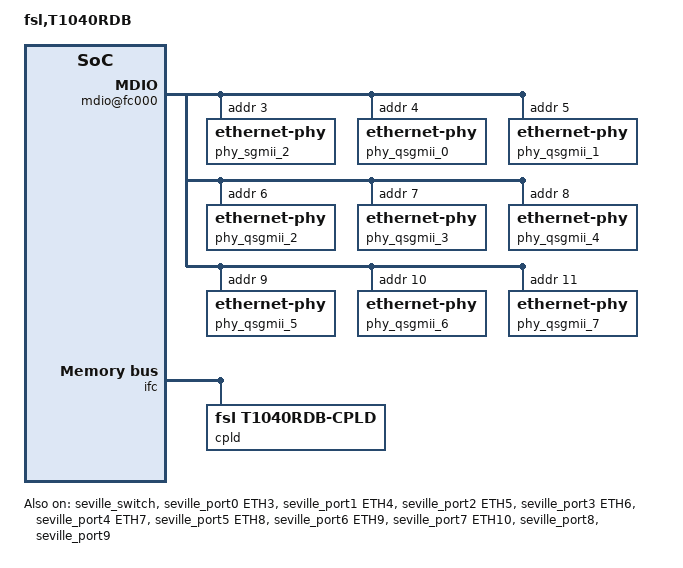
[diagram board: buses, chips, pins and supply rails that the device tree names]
/include/ "t104xsi-pre.dtsi"
/include/ "t104xrdb.dtsi"
/ {
	model = "fsl,T1040RDB";
	compatible = "fsl,T1040RDB";
	aliases {
		phy_sgmii_2 = &phy_sgmii_2;
	};
	soc@ffe000000 {
		fman@400000 {
			ethernet@e0000 {
				fixed-link = <0 1 1000 0 0>;
				phy-connection-type = "sgmii";
			};
			ethernet@e2000 {
				fixed-link = <1 1 1000 0 0>;
				phy-connection-type = "sgmii";
			};
			ethernet@e4000 {
				phy-handle = <&phy_sgmii_2>;
				phy-connection-type = "sgmii";
			};
			mdio@fc000 {
				phy_sgmii_2: ethernet-phy@3 {
					reg = <0x03>;
				};
				phy_qsgmii_0: ethernet-phy@4 {
					reg = <0x4>;
				};
				phy_qsgmii_1: ethernet-phy@5 {
					reg = <0x5>;
				};
				phy_qsgmii_2: ethernet-phy@6 {
					reg = <0x6>;
				};
				phy_qsgmii_3: ethernet-phy@7 {
					reg = <0x7>;
				};
				phy_qsgmii_4: ethernet-phy@8 {
					reg = <0x8>;
				};
				phy_qsgmii_5: ethernet-phy@9 {
					reg = <0x9>;
				};
				phy_qsgmii_6: ethernet-phy@a {
					reg = <0xa>;
				};
				phy_qsgmii_7: ethernet-phy@b {
					reg = <0xb>;
				};
			};
		};
	};
	ifc: localbus@ffe124000 {
		cpld@3,0 {
			compatible = "fsl,t1040rdb-cpld";
		};
	};
};
#include "t1040si-post.dtsi"
&seville_switch {
	status = "okay";
};
&seville_port0 {
	managed = "in-band-status";
	phy-handle = <&phy_qsgmii_0>;
	phy-mode = "qsgmii";
	label = "ETH3";
	status = "okay";
};
&seville_port1 {
	managed = "in-band-status";
	phy-handle = <&phy_qsgmii_1>;
	phy-mode = "qsgmii";
	label = "ETH4";
	status = "okay";
};
&seville_port2 {
	managed = "in-band-status";
	phy-handle = <&phy_qsgmii_2>;
	phy-mode = "qsgmii";
	label = "ETH5";
	status = "okay";
};
&seville_port3 {
	managed = "in-band-status";
	phy-handle = <&phy_qsgmii_3>;
	phy-mode = "qsgmii";
	label = "ETH6";
	status = "okay";
};
&seville_port4 {
	managed = "in-band-status";
	phy-handle = <&phy_qsgmii_4>;
	phy-mode = "qsgmii";
	label = "ETH7";
	status = "okay";
};
&seville_port5 {
	managed = "in-band-status";
	phy-handle = <&phy_qsgmii_5>;
	phy-mode = "qsgmii";
	label = "ETH8";
	status = "okay";
};
&seville_port6 {
	managed = "in-band-status";
	phy-handle = <&phy_qsgmii_6>;
	phy-mode = "qsgmii";
	label = "ETH9";
	status = "okay";
};
&seville_port7 {
	managed = "in-band-status";
	phy-handle = <&phy_qsgmii_7>;
	phy-mode = "qsgmii";
	label = "ETH10";
	status = "okay";
};
&seville_port8 {
	status = "okay";
};
&seville_port9 {
	status = "okay";
};
